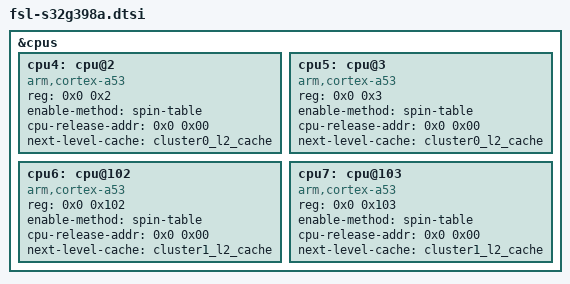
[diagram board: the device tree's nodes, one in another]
// SPDX-License-Identifier: GPL-2.0
/*
 * Copyright 2021 NXP
 *
 * This program is free software; you can redistribute it and/or modify
 * it under the terms of the GNU General Public License as published by
 * the Free Software Foundation; either version 2 of the License, or
 * (at your option) any later version.
 */

/dts-v1/;
#include "fsl-s32g.dtsi"

&cpus {
	cpu4: cpu@2 {
		device_type = "cpu";
		compatible = "arm,cortex-a53";
		reg = <0x0 0x2>;
		enable-method = "spin-table";
		cpu-release-addr = <0x0 0x00>;
		next-level-cache = <&cluster0_l2_cache>;
	};
	cpu5: cpu@3 {
		device_type = "cpu";
		compatible = "arm,cortex-a53";
		reg = <0x0 0x3>;
		enable-method = "spin-table";
		cpu-release-addr = <0x0 0x00>;
		next-level-cache = <&cluster0_l2_cache>;
	};
	cpu6: cpu@102 {
		device_type = "cpu";
		compatible = "arm,cortex-a53";
		reg = <0x0 0x102>;
		enable-method = "spin-table";
		cpu-release-addr = <0x0 0x00>;
		next-level-cache = <&cluster1_l2_cache>;
	};
	cpu7: cpu@103 {
		device_type = "cpu";
		compatible = "arm,cortex-a53";
		reg = <0x0 0x103>;
		enable-method = "spin-table";
		cpu-release-addr = <0x0 0x00>;
		next-level-cache = <&cluster1_l2_cache>;
	};
};
